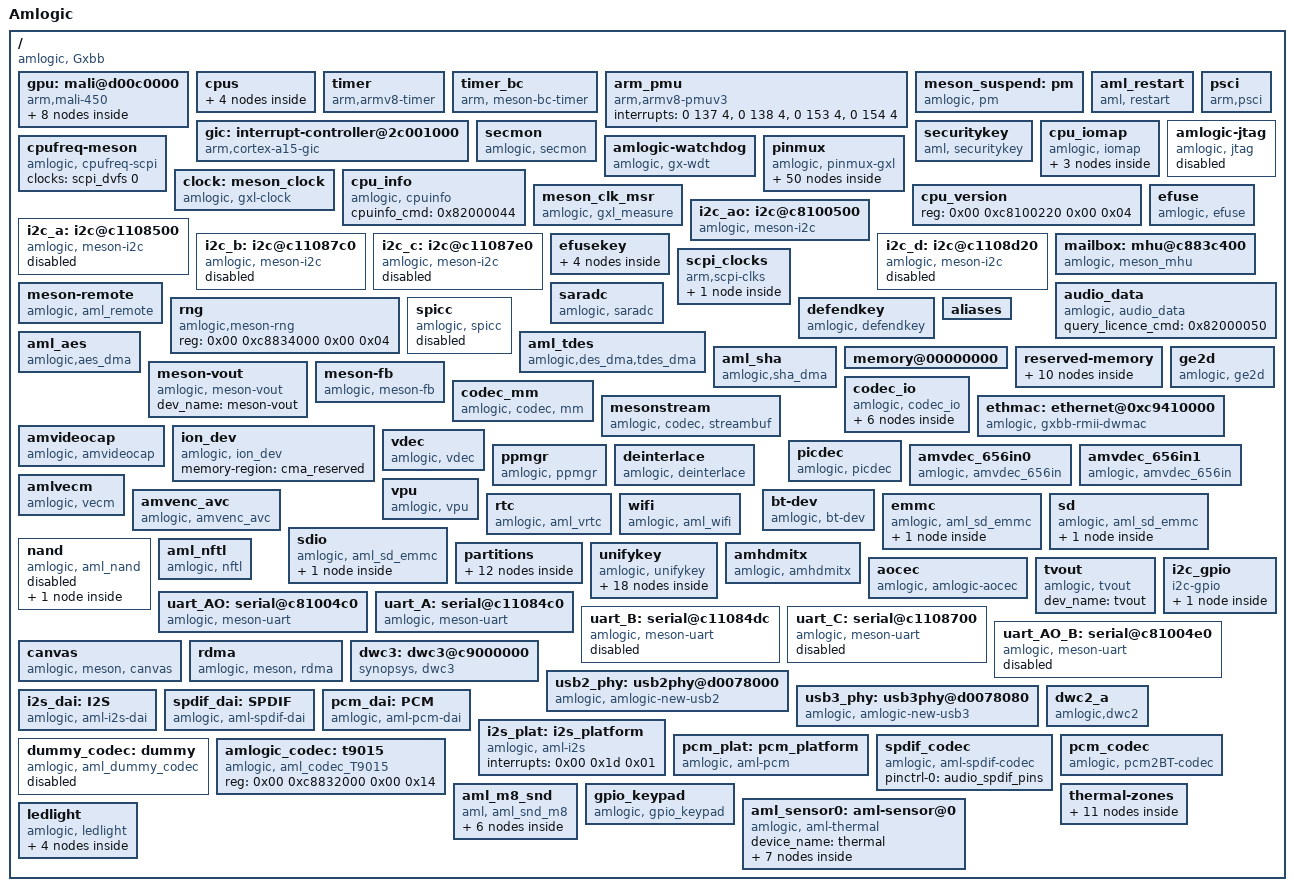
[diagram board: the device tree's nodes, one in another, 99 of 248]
/dts-v1/;

/ {
	le-dt-id = "gxl_p212_1g";
	model = "Amlogic";
	compatible = "amlogic, Gxbb";
	amlogic-dt-id = "gxl_p212_1g";
	interrupt-parent = < 0x01 >;
	#address-cells = < 0x02 >;
	#size-cells = < 0x02 >;

	gpu: mali@d00c0000 {
		#cooling-cells = < 0x02 >;	/* min followed by max */
		compatible = "arm,mali-450";
		interrupt-parent = < &gic >;
		reg = < 0 0xd00c0000 0 0x40000 >, /*mali APB bus base address*/
			 < 0 0xc1104440 0 0x01000 >, /*reset register*/
			 < 0 0xc8100000 0 0x01000 >, /*aobus base address for gpu pmu domain*/
			 < 0 0xc883c000 0 0x01000 >, /*hiubus base address for gpu clk cntl*/
			 < 0 0xc1104440 0 0x01000 >;
		interrupts = < 0 160 4 >, < 0 161 4 >, < 0 162 4 >, < 0 163 4 >,
				< 0 164 4 >, < 0 165 4 >, < 0 166 4 >, < 0 167 4 >,
				< 0 168 4 >, < 0 169 4 >;
		interrupt-names = "IRQGP", "IRQGPMMU", "IRQPP", "IRQPMU",
			"IRQPP0", "IRQPPMMU0", "IRQPP1", "IRQPPMMU1",
			"IRQPP2", "IRQPPMMU2";
		pmu_domain_config = < 0x01 0x02 0x04 0x04 0x00 0x00 0x00 0x00 0x00 0x01 0x02 0x00 >;
		pmu_switch_delay = < 0xffff >;
		num_of_pp = < 0x03 >;
		def_clock = < 0x03 >;
		sc_mpp = < 0x03 >;	/* number of pp used most of time.*/
		tbl = < &clk125_cfg &clk285_cfg &clk400_cfg &clk500_cfg &clk666_cfg &clk750_cfg >;

		clocks = < &clock CLK_FPLL_DIV3 >,
			< &clock CLK_FPLL_DIV4 >,
			< &clock CLK_FPLL_DIV5 >,
			< &clock CLK_FPLL_DIV7 >,
			< &clock GP0_PLL >,
			< &clock CLK_MALI >,
			< &clock CLK_MALI_0 >,
			< &clock CLK_MALI_1 >;
		clock-names = "fclk_div3", "fclk_div4", "fclk_div5", "fclk_div7", "gp0_pll", "clk_mali", "clk_mali_0", "clk_mali_1";

		/*control_interval x keep_count =  = 900 - 1000ms */
		control_interval = < 0xc8 >; //200

		 clk125_cfg: clk125_cfg {
			clk_freq = < 0x7735940 >; //125000000
			clk_parent = "fclk_div4";
			clkp_freq = < 0x1dcd6500 >; //500000000
			voltage = < 0x47e >; //1150
			keep_count = < 0x05 >;
			threshold = < 0x1e 0xfa >; //30 250
		};

		 clk250_cfg: clk250_cfg {
			clk_freq = < 0xee6b280 >; //250000000
			clk_parent = "fclk_div4";
			clkp_freq = < 0x1dcd6500 >; //500000000
			voltage = < 0x47e >; //1150
			keep_count = < 0x05 >;
			threshold = < 0x73 0xfa >; //115 250
			/*125 = 250*(125/250), 50 = 60-10*/
		};

		 clk285_cfg: clk285_cfg {
			clk_freq = < 0x10fcc140 >; //285000000
			clk_parent = "fclk_div7";
			clkp_freq = < 0x10fcc140 >; //285000000
			voltage = < 0x47e >; //1150
			keep_count = < 0x05 >;
			threshold = < 0x64 0xfa >; //100 250
			/*109 = 250*(125/285)*/
		};

		 clk400_cfg: clk400_cfg {
			clk_freq = < 0x17d78400 >; //400000000
			clk_parent = "fclk_div5";
			clkp_freq = < 0x17d78400 >; //400000000
			voltage = < 0x47e >; //1150
			keep_count = < 0x03 >;
			threshold = < 0xa8 0xfa >; //168 250
			/*178 = 250*(285/400)*/
		};

		 clk500_cfg: clk500_cfg {
			clk_freq = < 0x1dcd6500 >; //500000000
			clk_parent = "fclk_div4";
			clkp_freq = < 0x1dcd6500 >; //500000000
			voltage = < 0x47e >; //1150
			keep_count = < 0x02 >;
			threshold = < 0xbe 0xfa >; //190 250
			/*200 = 250*(400/500)*/
		};

		 clk666_cfg: clk666_cfg {
			clk_freq = < 0x27b25a80 >; //666000000
			clk_parent = "fclk_div3";
			clkp_freq = < 0x27b25a80 >; //666000000
			voltage = < 0x47e >; //1150
			keep_count = < 0x01 >;
			threshold = < 0xb1 0xfa >; //177 250
			/*187.5 = 250*(500/666.6)*/
		};

		 clk750_cfg: clk750_cfg {
			clk_freq = < 0x2c588a00 >; //744000000
			clk_parent = "gp0_pll";
			clkp_freq = < 0x2c588a00 >; //744000000
			voltage = < 0x47e >; //1150
			keep_count = < 0x01 >;
			threshold = < 0xd5 0xff >; //213 255
			/*223 = 250*(666.0/744.0), 223+7 = 230*/
		};

		 clk800_cfg: clk800_cfg {
			clk_freq = < 0x2f34f600 >; //792000000
			clk_parent = "gp0_pll";
			clkp_freq = < 0x2f34f600 >; //792000000
			voltage = < 0x47e >; //1150
			keep_count = < 0x01 >;
			threshold = < 0xe6 0xff >; //230 255
		};
	};

	cpus: cpus {
		#address-cells = < 0x02 >;
		#size-cells = < 0x00 >;
		#cooling-cells = < 2 >;	/* min followed by max */

		cpu0: cpu@0 {
			device_type = "cpu";
			compatible = "arm,cortex-a53", "arm,armv8";
			reg = < 0x00 0x00 >;
			enable-method = "psci";
		};

		cpu1: cpu@1 {
			device_type = "cpu";
			compatible = "arm,cortex-a53", "arm,armv8";
			reg = < 0x00 0x01 >;
			enable-method = "psci";
		};

		cpu2: cpu@2 {
			device_type = "cpu";
			compatible = "arm,cortex-a53", "arm,armv8";
			reg = < 0x00 0x02 >;
			enable-method = "psci";
		};

		cpu3: cpu@3 {
			device_type = "cpu";
			compatible = "arm,cortex-a53", "arm,armv8";
			reg = < 0x00 0x03 >;
			enable-method = "psci";
		};
	};

	timer {
		compatible = "arm,armv8-timer";
		interrupts = < GIC_PPI 13 0xff01 >, 
				 < GIC_PPI 14 0xff01 >,
				 < GIC_PPI 11 0xff01 >,
				 < GIC_PPI 10 0xff01 >;
	};	/* GIC_PPI: 1*/

	timer_bc {
		compatible = "arm, meson-bc-timer";
		reg = < 0x00 0xc1109990 0x00 0x04
			0x00 0xc1109994 0x00 0x04 >;
		timer_name = "Meson TimerF";
		clockevent-rating = < 0x12c >;
		clockevent-shift = < 0x14 >;
		clockevent-features = < 0x23 >;
		interrupts = < 0x00 0x3c 0x01 >;
		bit_enable = < 0x10 >;
		bit_mode = < 0x0c >;
		bit_resolution = < 0x00 >;
	};

	arm_pmu {
		compatible = "arm,armv8-pmuv3";
		interrupts = < 0 137 4 >,
				 < 0 138 4 >,
				 < 0 153 4 >,
				 < 0 154 4 >;
	};

	meson_suspend: pm {
		compatible = "amlogic, pm";
		device_name = "aml_pm";
		gxbaby-suspend;
		reg = < 0x00 0xc81000a8 0x00 0x04
			0x00 0xc810023c 0x00 0x04 >;
	};

	gic: interrupt-controller@2c001000 {
		compatible = "arm,cortex-a15-gic", "arm,cortex-a9-gic";
		#interrupt-cells = < 0x03 >;
		#address-cells = < 0x00 >;
		interrupt-controller;
		reg = < 0x00 0xc4301000 0x00 0x1000
			0x00 0xc4302000 0x00 0x100 >;
		interrupts = < GIC_PPI 0x09 0xf04 >;	/* GIC_PPI: 1*/
	};

	aml_restart {
		compatible = "aml, restart";
		sys_reset = < 0x84000009 >;
		sys_poweroff = < 0x84000008 >;
	};

	psci {
		compatible = "arm,psci";
		method = "smc";
		cpu_suspend = < 0xc4000001 >;
		cpu_off = < 0x84000002 >;
		cpu_on = < 0xc4000003 >;
		migrate = < 0xc4000005 >;
	};

	secmon {
		compatible = "amlogic, secmon";
		memory-region = < &secmon_reserved >;
		in_base_func = < 0x82000020 >;
		out_base_func = < 0x82000021 >;
	};

	securitykey {
		compatible = "aml, securitykey";
		storage_query = < 0x82000060 >;
		storage_read = < 0x82000061 >;
		storage_write = < 0x82000062 >;
		storage_tell = < 0x82000063 >;
		storage_verify = < 0x82000064 >;
		storage_status = < 0x82000065 >;
		storage_list = < 0x82000067 >;
		storage_remove = < 0x82000068 >;
		storage_in_func = < 0x82000023 >;
		storage_out_func = < 0x82000024 >;
		storage_block_func = < 0x82000025 >;
		storage_size_func = < 0x82000027 >;
	};

	cpu_iomap {
		compatible = "amlogic, iomap";
		#address-cells = < 0x02 >;
		#size-cells = < 0x02 >;
		ranges;

		io_cbus_base {
			reg = < 0x00 0xc1100000 0x00 0x100000 >;
		};

		io_apb_base {
			reg = < 0x00 0xd0000000 0x00 0x200000 >;
		};

		io_aobus_base {
			reg = < 0x00 0xc8100000 0x00 0x100000 >;
		};
	};

	cpufreq-meson {
		compatible = "amlogic, cpufreq-scpi";
		status = "okay";
		clocks = < &scpi_dvfs 0 >;
		clock-names = "cpu_clk";
	};

	amlogic-watchdog {
		compatible = "amlogic, gx-wdt";
		status = "okay";
		default_timeout = < 0x0a >;
		reset_watchdog_method = < 1 >; //0: sysfs,1: kernel
		reset_watchdog_time = < 0x02 >;
		shutdown_timeout = < 0x0a >;
		firmware_timeout = < 0x06 >;
		suspend_timeout = < 0x06 >;
		reg = < 0x00 0xc11098d0 0x00 0x10 >;
		clocks = < &clock CLK_XTAL >;
	};

	amlogic-jtag {
		compatible = "amlogic, jtag";
		status = "disabled";
		pinctrl-names = "jtag_apao_pins", "jtag_apee_pins";
		pinctrl-0 = < &jtag_apao_pins >;
		pinctrl-1 = < &jtag_apee_pins >;
	};

	clock: meson_clock {
		compatible = "amlogic, gxl-clock";
		reg = < 0x0 0xc883c000 0x0 0x1000 >,	/* HIU BUS */
			 < 0x0 0xc8100000 0x0 0x1000 >;	/* AOBUS */
		#clock-cells = < 0x01 >;
		#reset-cells = < 0x01 >;
		sys_max = < 0x5b8d8000 >;
	};

	cpu_info {
		compatible = "amlogic, cpuinfo";
		cpuinfo_cmd = < 0x82000044 >;
	};

	pinmux: pinmux {
		compatible = "amlogic, pinmux-gxl";
		dev_name = "pinmux";
		#pinmux-cells = < 0x02 >;
		#address-cells = < 0x02 >;
		#size-cells = < 0x02 >;
		reg = < 0x00 0xc1109880 0x00 0x10 >;
		ranges;

		gpio: banks@c11080b0 {
			reg = < 0x0 0xc88344b0 0x0 0x28 >,
				 < 0x0 0xc88344e8 0x0 0x14 >,
				 < 0x0 0xc8834520 0x0 0x14 >,
				 < 0x0 0xc8834430 0x0 0x40 >;
			reg-names = "mux", "pull", "pull-enable", "gpio";
			gpio-controller;
			#gpio-cells = < 0x02 >;
		};

		gpio_ao: ao-bank@c1108030 {
			reg = < 0x0 0xc8100014 0x0 0x8 >,
				 < 0x0 0xc810002c 0x0 0x4 >,
				 < 0x0 0xc8100024 0x0 0x8 >;
			reg-names = "mux", "pull", "gpio";
			gpio-controller;
			#gpio-cells = < 0x02 >;
		};

		external_eth_pins {
			amlogic,setmask = < 0x04 0xfffc00 >;
			amlogic,clrmask = < 0x04 0x3fc 0x03 0xffcff800 >;
			amlogic,pins = "GPIOZ_0", "GPIOZ_1", "GPIOZ_2", "GPIOZ_3", "GPIOZ_4", "GPIOZ_5", "GPIOZ_6",
			"GPIOZ_7", "GPIOZ_8", "GPIOZ_9", "GPIOZ_10", "GPIOZ_11", "GPIOZ_12", "GPIOZ_13";
		};

		internal_eth_pins: internal_eth_pins {
			amlogic,setmask = < 0x04 0x3000000 >;
			amlogic,clrmask = < 0x03 0x300000 >;
			amlogic,pins = "GPIOZ_14", "GPIOZ_15";
		};

		jtag_apao_pins: jtag_apao_pin {
			amlogic,clrmask = < 0x06 0x7fe0000 >;
			amlogic,pins = "GPIOH_6", "GPIOH_7", "GPIOH_8", "GPIOH_9";
		};

		jtag_apee_pins: jtag_apee_pin{
			amlogic,clrmask = < 0x06 0x3c >;
			amlogic,pins = "CARD_0", "CARD_1", "CARD_2", "CARD_3";
		};

		remote_pin {
			amlogic,setmask = < 0x10 0x01 >;
			amlogic,pins = "GPIOAO_7";
		};

		ao_uart {
			amlogic,setmask = < 0x10 0x1800 >;
			amlogic,pins = "GPIOAO_0", "GPIOAO_1";
		};

		ao_b_uart_pins: ao_b_uart {
			amlogic,setmask = < 0x10 0x1800000 >;
			amlogic,pins = "GPIOAO_4", "GPIOAO_5";
		};

		uart_a_pins: a_uart {
			amlogic,setmask = < 0x05 0xf0000 >;
			amlogic,clrmask = < 0x05 0x3c0 >;
			amlogic,pins = "GPIOX_12", "GPIOX_13", "GPIOX_14", "GPIOX_15";
		};

		b_uart_pins: b_uart {
			amlogic,setmask = < 0x02 0x18000 >;
			amlogic,pins = "GPIODV_24", "GPIODV_25";
		};

		c_uart_pins: c_uart {
			amlogic,setmask = < 0x05 0x3000 >;
			amlogic,pins = "GPIOX_8", "GPIOX_9";
		};

		wifi_32k_pins: wifi_32k_pins {
			amlogic,setmask = < 0x05 0x8000 >;
			amlogic,pins = "GPIOX_16";
		};

		sd_clk_cmd_pins: sd_clk_cmd_pins{
			amlogic,setmask = < 0x06 0x0c 0x10 0x1800 >;
			amlogic,pins = "CARD_2", "CARD_3";	/* CARD_2: CLK, CARD_3: CMD */
			amlogic,enable-output = < 0x01 >;	/* 0: output, 1: input */
			amlogic,pullup = < 0x01 >;
			amlogic,pullupen = < 0x01 >;
		};

		sd_all_pins: sd_all_pins{
			amlogic,setmask = < 0x06 0x3f 0x10 0x1800 >;
			amlogic,clrmask = < 0x06 0xfc0 >;
			amlogic,pins = "CARD_0", "CARD_1", "CARD_2", "CARD_3", "CARD_4", "CARD_5";
			amlogic,enable-output = < 0x01 >;	/* 0: output, 1: input */
			amlogic,pullup = < 0x01 >;
			amlogic,pullupen = < 0x01 >;
		};

		sd_1bit_pins: sd_1bit_pins{
			amlogic,setmask = < 0x06 0x1c 0x10 0x1800 >;
			amlogic,clrmask = < 0x06 0xcc3 >;
			amlogic,pins = "CARD_1", "CARD_2", "CARD_3";
			amlogic,enable-output = < 0x01 >;	/* 0: output, 1: input */
			amlogic,pullup = < 0x01 >;
			amlogic,pullupen = < 0x01 >;
		};

		sd_clk_cmd_uart_pins: sd_clk_cmd_uart_pins{
			amlogic,setmask = < 0x06 0x30c >;
			amlogic,clrmask = < 0x06 0xcc3 0x10 0x1800 >;
			amlogic,pins = "CARD_2", "CARD_3";	/* CARD_2: CLK, CARD_3: CMD */
			amlogic,enable-output = < 0x01 >;	/* 0: output, 1: input */
			amlogic,pullup = < 0x01 >;
			amlogic,pullupen = < 0x01 >;
		};

		sd_1bit_uart_pins: sd_1bit_uart_pins{
			amlogic,setmask = < 0x06 0x31c >;
			amlogic,clrmask = < 0x06 0xcc3 0x10 0x1800 >;
			amlogic,pins = "CARD_1", "CARD_2", "CARD_3";
			amlogic,enable-output = < 0x01 >;	/* 0: output, 1: input */
			amlogic,pullup = < 0x01 >;
			amlogic,pullupen = < 0x01 >;
		};

		sd_to_ao_uart_pins: sd_to_ao_uart_pins {
			amlogic,setmask = < 0x10 0x1800 >;
			amlogic,clrmask = < 0x06 0x300 >;
			amlogic,pins = "GPIOAO_0", "GPIOAO_1";
			amlogic,enable-output = < 0x01 >;
			amlogic,pullup = < 0x01 >;
			amlogic,pullupen = < 0x01 >;
		};

		ao_to_sd_uart_pins: ao_to_sd_uart_pins {
			amlogic,setmask = < 0x06 0x300 >;
			amlogic,clrmask = < 0x10 0x1800 0x06 0xcc3 >;
			amlogic,pins = "CARD_4", "CARD_5";
			amlogic,enable-output = < 0x01 >;	/* 0: output, 1: input */
			amlogic,pullup = < 0x01 >;
			amlogic,pullupen = < 0x01 >;
		};
		/* switch jtag pins to card from apao */
		ao_to_sd_jtag_pins: ao_to_sd_jtag_pins{
			amlogic,setmask = < 0x06 0x300 >;	/*set for uart-ee, fixme? */
			amlogic,clrmask = < 0x06 0xcff 0x10 0x1800 >;	/* clear for jtag */ /* clear for uart-ee, fixme? */
			amlogic,pins = "CARD_4", "CARD_5";	/* should be CARD_0/1/2/3 */
			amlogic,enable-output = < 0x01 >;	/* 0: output, 1: input */
			amlogic,pullup = < 0x01 >;
			amlogic,pullupen = < 0x01 >;
		};

		sd_to_ao_jtag_pins: sd_to_ao_jtag_pins {
			amlogic,setmask = < 0x10 0x1800 >;
			amlogic,clrmask = < 0x06 0xfc0 >;
			amlogic,pins = "GPIOAO_0", "GPIOAO_1";
			amlogic,enable-output = < 0x01 >;
			amlogic,pullup = < 0x01 >;
			amlogic,pullupen = < 0x01 >;
		};

		emmc_clk_cmd_pins: emmc_clk_cmd_pins{
			amlogic,setmask = < 0x07 0x60000000 >;
			amlogic,clrmask = < 0x07 0xe0 >;
			amlogic,pins = "BOOT_8", "BOOT_10";	/** BOOT_10: CMD, BOOT_8: CLK */
			amlogic,enable-output = < 0x01 >;	/** 0: output, 1: input */
			amlogic,pullup = < 0x01 >;
			amlogic,pullupen = < 0x01 >;
		};

		emmc_conf_pull_up: emmc_conf_pull_up{
			amlogic,pins = "BOOT_0", "BOOT_1", "BOOT_2", "BOOT_3", "BOOT_4",
					"BOOT_5", "BOOT_6", "BOOT_7", "BOOT_8", "BOOT_10";
			amlogic,pullup = < 0x01 >;
			amlogic,pullupen = < 0x01 >;
		};

		emmc_conf_pull_done: emmc_conf_pull_done{
			amlogic,pins = "BOOT_15";
			amlogic,pullup = < 0x00 >;
			amlogic,pullupen = < 0x01 >;
		};

		emmc_all_pins: emmc_all_pins {
			amlogic,setmask = < 0x07 0xf0000000 >;
			amlogic,clrmask = < 0x07 0xe0 >;
			amlogic,pins = "BOOT_0", "BOOT_1", "BOOT_2", "BOOT_3", "BOOT_4", "BOOT_5", "BOOT_6", "BOOT_7", "BOOT_8", "BOOT_10", "BOOT_15";
			amlogic,enable-output = < 0x01 >;
		};

		sdio_clk_cmd_pins: sdio_clk_cmd_pins {
			amlogic,setmask = < 0x05 0xc000000 >;
			amlogic,pins = "GPIOX_4", "GPIOX_5";
			amlogic,enable-output = < 0x01 >;
			amlogic,pullup = < 0x01 >;
			amlogic,pullupen = < 0x01 >;
		};

		sdio_all_pins: sdio_all_pins {
			amlogic,setmask = < 0x05 0xfc000000 >;
			amlogic,pins = "GPIOX_0", "GPIOX_1", "GPIOX_2", "GPIOX_3", "GPIOX_4", "GPIOX_5";
			amlogic,enable-output = < 0x01 >;
			amlogic,pullup = < 0x01 >;
			amlogic,pullupen = < 0x01 >;
		};

		conf_nand_pulldown: conf_nand_pulldown {
			amlogic,pins = "BOOT_0", "BOOT_1", "BOOT_2", "BOOT_3", "BOOT_4", "BOOT_5", "BOOT_6", "BOOT_7", "BOOT_15";
			amlogic,pullup = < 0x00 >;
			amlogic,pullupen = < 0x01 >;
		};

		conf_nand_pullup: conf_nand_pullup {
			amlogic,pins = "BOOT_8", "BOOT_10";
			amlogic,pullup = < 0x01 >;
			amlogic,pullupen = < 0x01 >;
		};

		all_nand_pins: all_nand_pins {
			amlogic,setmask = < 0x07 0x800000ff >;
			amlogic,clrmask = < 0x07 0x70ffbc00 >;
			amlogic,pins = "BOOT_0", "BOOT_1", "BOOT_2", "BOOT_3", "BOOT_4", "BOOT_5", "BOOT_6", "BOOT_7", "BOOT_8", "BOOT_9", "BOOT_10", "BOOT_11", "BOOT_12", "BOOT_13", "BOOT_14", "BOOT_15";
			amlogic,enable-output = < 0x01 >;
		};

		nand_cs: nand_cs {
			amlogic,setmask = < 0x07 0xc0 >;
			amlogic,clrmask = < 0x07 0x40040000 >;
			amlogic,pins = "BOOT_8", "BOOT_9";
		};

		hdmitx_hpd: hdmitx_hpd {
			amlogic,setmask = < 0x06 0x80000000 >;
			amlogic,pins = "GPIOH_0";
		};

		hdmitx_ddc: hdmitx_ddc {
			amlogic,setmask = < 0x06 0x30000000 >;
			amlogic,pins = "GPIOH_1", "GPIOH_2";
		};

		hdmitx_aocec: hdmitx_aocec {
			amlogic,setmask = < 0x10 0x8000 >;
			amlogic,clrmask = < 0x10 0x24000 0x11 0x01 >;
			amlogic,pins = "GPIOAO_8";
		};

		hdmitx_eecec: hdmitx_eecec {
			amlogic,setmask = < 0x10 0x4000 >;
			amlogic,clrmask = < 0x10 0x28000 0x11 0x01 >;
			amlogic,pins = "GPIOAO_8";
		};

		ao_i2c_master: ao_i2c{
			amlogic,setmask = < AO 0x60 >;	/* AO: 0x10 */
			amlogic,clrmask = < AO 0x1800006 >;
			amlogic,pins = "GPIOAO_4", "GPIOAO_5";
		};

		i2c_a_master: i2c_a{
			amlogic,setmask = < 0x01 0xc000 >;
			amlogic,clrmask = < 0x03 0x18 0x02 0x18000 0x02 0xc0 0x01 0x600000 >;
			amlogic,pins = "GPIODV_24", "GPIODV_25";
		};

		i2c_b_master: i2c_b{
			amlogic,setmask = < 0x01 0x3000 >;
			amlogic,clrmask = < 0x02 0x6000 0x01 0x1c0000 >;
			amlogic,pins = "GPIODV_26", "GPIODV_27";
		};

		i2c_c_master: i2c_c{
			amlogic,setmask = < 0x01 0xc00 >;
			amlogic,clrmask = < 0x02 0x1800 0x01 0x200 0x02 0x20 >;
			amlogic,pins = "GPIODV_28", "GPIODV_29";
		};

		i2c_d_master: i2c_d{
			amlogic,setmask = < 0x05 0x30 >;
			amlogic,clrmask = < 0x05 0x300c03 >;
			amlogic,pins = "GPIOX_10", "GPIOX_11";
		};

		spicc_pins_z11z12z13 {
			amlogic,setmask = < 0x04 0x1c >;
			amlogic,clrmask = < 0x03 0x800 0x04 0x1c00 >;
			amlogic,pins = "GPIOZ_11", "GPIOZ_12", "GPIOZ_13";
		};

		spicc_pulldown_z11z12z13 {
			amlogic,pins = "GPIOZ_11", "GPIOZ_12", "GPIOZ_13";
			amlogic,pullup = < 0x00 >;
			amlogic,pullupen = < 0x01 >;
		};

		spicc_pullup_z11z12z13 {
			amlogic,pins = "GPIOZ_11", "GPIOZ_12", "GPIOZ_13";
			amlogic,pullup = < 0x01 >;
			amlogic,pullupen = < 0x01 >;
		};

		spicc_pins_x8x9x11 {
			amlogic,setmask = < 0x05 0x0d >;
			amlogic,clrmask = < 0x05 0xd03430 0x06 0x0d >;
			amlogic,pins = "GPIOX_8", "GPIOX_9", "GPIOX_11";
		};

		spicc_pulldown_x8x9x11 {
			amlogic,pins = "GPIOX_8", "GPIOX_9", "GPIOX_11";
			amlogic,pullup = < 0x00 >;
			amlogic,pullupen = < 0x01 >;
		};

		spicc_pullup_x8x9x11 {
			amlogic,pins = "GPIOX_8", "GPIOX_9", "GPIOX_11";
			amlogic,pullup = < 0x01 >;
			amlogic,pullupen = < 0x01 >;
		};

		audio_pins: audio_pin {
			amlogic,setmask = < 0x06 0x7800000 >;
			amlogic,clrmask = < 0x06 0x7e0000 >;
			amlogic,pins = "GPIOH_6", "GPIOH_7", "GPIOH_8", "GPIOH_9";
		};

		audio_spdif_pins: audio_pin1 {
			amlogic,setmask = < 0x06 0x10000000 >;	/*spdif_out*/
			amlogic,clrmask = < 0x06 0x8000000 >;
			amlogic,pins = "GPIOH_4";
		};

		audio_btpcm_pins: audio_btpcm_pins {
			amlogic,setmask = < 0x05 0xf00000 >;
			amlogic,clrmask = < 0x05 0x3c33 >;
			amlogic,pins = "GPIOX_8", "GPIOX_9", "GPIOX_10", "GPIOX_11";
		};
	};	/* end of pinmux */

	cpu_version {
		reg = < 0x00 0xc8100220 0x00 0x04 >;
	};

	meson_clk_msr {
		compatible = "amlogic, gxl_measure";
		reg = < 0x00 0xc110875c 0x00 0x04
			0x00 0xc1108764 0x00 0x04 >;
	};

	i2c_ao: i2c@c8100500{ /*I2C-AO*/
		compatible = "amlogic, meson-i2c";
		dev_name = "i2c-AO";
		status = "okay";
		reg = < 0x00 0xc8100500 0x00 0x1d >;
		device_id = < 0x00 >;
		pinctrl-names = "default";
		pinctrl-0 = < &ao_i2c_master >;
		#address-cells = < 0x01 >;
		#size-cells = < 0x00 >;
		use_pio = < 0x00 >;
		master_i2c_speed = < 0x493e0 >;
		clocks = < &clock CLK_81 >;
		clock-names = "clk_i2c";
		resets = < &clock GCLK_IDX_I2C >;	/* GCLK_IDX_I2C: 0x09 */
	};

	i2c_a: i2c@c1108500 { /*I2C-A*/
		compatible = "amlogic, meson-i2c";
		dev_name = "i2c-A";
		status = "disabled";
		reg = < 0x00 0xc1108500 0x00 0x20 >;
		device_id = < 0x01 >;
		pinctrl-names = "default";
		pinctrl-0 = < &i2c_a_master >;	/*p200 i2c-A multiplex with usb PWR*/
		#address-cells = < 0x01 >;
		#size-cells = < 0x00 >;
		use_pio = < 0x00 >;
		master_i2c_speed = < 0x493e0 >;
		clocks = < &clock CLK_81 >;
		clock-names = "clk_i2c";
		resets = < &clock GCLK_IDX_I2C >;	/* GCLK_IDX_I2C: 0x09 */
	};

	i2c_b: i2c@c11087c0 { /*I2C-B*/
		compatible = "amlogic, meson-i2c";
		dev_name = "i2c-B";
		status = "disabled";
		reg = < 0x00 0xc11087c0 0x00 0x20 >;
		device_id = < 0x02 >;
		pinctrl-names = "default";
		pinctrl-0 = < &i2c_b_master >;
		#address-cells = < 0x01 >;
		#size-cells = < 0x00 >;
		use_pio = < 0x00 >;
		master_i2c_speed = < 0x493e0 >;
		clocks = < &clock CLK_81 >;
		clock-names = "clk_i2c";
		resets = < &clock GCLK_IDX_I2C >;	/* GCLK_IDX_I2C: 0x09 */
	};

	i2c_c: i2c@c11087e0 { /*I2C-C*/
		compatible = "amlogic, meson-i2c";
		dev_name = "i2c-C";
		status = "disabled";
		reg = < 0x00 0xc11087e0 0x00 0x20 >;
		device_id = < 0x03 >;
		pinctrl-names = "default";
		pinctrl-0 = < &i2c_c_master >;
		#address-cells = < 0x01 >;
		#size-cells = < 0x00 >;
		use_pio = < 0x00 >;
		master_i2c_speed = < 0x493e0 >;
		clocks = < &clock CLK_81 >;
		clock-names = "clk_i2c";
		resets = < &clock GCLK_IDX_I2C >;	/* GCLK_IDX_I2C: 0x09 */
	};

	i2c_d: i2c@c1108d20 { /*I2C-D*/
		compatible = "amlogic, meson-i2c";
		dev_name = "i2c-D";
		status = "disabled";
		reg = < 0x00 0xc1108d20 0x00 0x20 >;
		device_id = < 0x04 >;
		pinctrl-names = "default";
		pinctrl-0 = < &i2c_d_master >;
		#address-cells = < 0x01 >;
		#size-cells = < 0x00 >;
		use_pio = < 0x00 >;
		master_i2c_speed = < 0x493e0 >;
		clocks = < &clock CLK_81 >;
		clock-names = "clk_i2c";
		resets = < &clock GCLK_IDX_I2C >;	/* GCLK_IDX_I2C: 0x09 */
	};

	efuse {
		compatible = "amlogic, efuse";
		read_cmd = < 0x82000030 >;
		write_cmd = < 0x82000031 >;
		get_max_cmd = < 0x82000033 >;
		key = < &efusekey >;
		resets = < &clock GCLK_IDX_EFUSE >;	/* GCLK_IDX_EFUSE: 0x3e */
		reset-names = "efuse_clk";
		status = "okay";
	};

	efusekey: efusekey {
		keynum = < 0x04 >;
		key0 = < &key_0 >;
		key1 = < &key_1 >;
		key2 = < &key_2 >;
		key3 = < &key_3 >;

		key_0: key_0{
			keyname = "mac";
			offset = < 0x00 >;
			size = < 0x06 >;
		};

		key_1: key_1{
			keyname = "mac_bt";
			offset = < 0x06 >;
			size = < 0x06 >;
		};

		key_2: key_2{
			keyname = "mac_wifi";
			offset = < 0x0c >;
			size = < 0x06 >;
		};

		key_3: key_3{
			keyname = "usid";
			offset = < 0x12 >;
			size = < 0x10 >;
		};
	};

	mailbox: mhu@c883c400 {
		compatible = "amlogic, meson_mhu";
		reg = < 0x0 0xc883c400 0x0 0x4c >,	/* MHU registers */
			 < 0x0 0xc8013000 0x0 0x800 >;	/* Payload area */
		interrupts = < 0 209 IRQ_TYPE_EDGE_RISING >,	/* low priority interrupt */
				 < 0 210 IRQ_TYPE_EDGE_RISING >;	/* high priority interrupt */
		#mbox-cells = < 0x01 >;
		mbox-names = "cpu_to_scp_low", "cpu_to_scp_high";
		mboxes = < &mailbox 0 &mailbox 1 >;
	};

	scpi_clocks {
		compatible = "arm,scpi-clks";

		scpi_dvfs: scpi_clocks@0 {
			compatible = "arm,scpi-clk-indexed";
			#clock-cells = < 0x01 >;
			clock-indices = < 0x00 >;
			clock-output-names = "vcpu";
		};
	};

	meson-remote {
		compatible = "amlogic, aml_remote";
		dev_name = "meson-remote";
		status = "okay";
		remote_ao_offset = < 0x580 >;
		interrupts = < 0x00 0xc4 0x01 >;
		pinctrl-names = "default";
		pinctrl-0 = < 0x18 >;
	};

	rng {
		compatible = "amlogic,meson-rng";
		reg = < 0x00 0xc8834000 0x00 0x04 >;
	};

	audio_data: audio_data {
		compatible = "amlogic, audio_data";
		query_licence_cmd = < 0x82000050 >;
		status = "okay";
	};

	saradc: saradc {
		compatible = "amlogic, saradc";
		status = "okay";
		interrupts = < 0x00 0x09 0x01 >;
		interrupt-names = "saradc_int";
		clocks = < &clock CLK_XTAL >;
		clock-names = "saradc_clk";
		resets = < &clock GCLK_IDX_SARADC >;	/* GCLK_IDX_SARADC: 0x56 */
		reg = < 0x00 0xc1108680 0x00 0x30
			0x00 0xc883c3d8 0x00 0x08 >;
	};

	defendkey: defendkey {
		compatible = "amlogic, defendkey";
		reg = < 0x00 0xc8834500 0x00 0x04 >;	/*RAND64_ADDR0*/
		mem_size = < 0x00 0x100000 >;
		status = "okay";
	};

	spicc: spicc {
		compatible = "amlogic, spicc";
		status = "disabled";
		reg = < 0x00 0xc1108d80 0x00 0x28 >;
		resets = < &clock GCLK_IDX_SPICC >;	/* GCLK_IDX_SPICC: 0x08 */
		// reset-names = "spicc_clk";
		clocks = < &clock CLK_81 >;
		clock-names = "spicc_clk";
		interrupts = < 0x00 0x51 0x01 >;
		device_id = < 0x00 >;
		//enhance = < 1 >;
	};

	aml_aes {
		compatible = "amlogic,aes_dma";
		dev_name = "aml_aes_dma";
		interrupts = < 0x00 0xbc 0x01
				0x00 0xbd 0x01 >;
		reg = < 0x00 0xc883e000 0x00 0x28 >;
	};

	aml_tdes {
		compatible = "amlogic,des_dma,tdes_dma";
		dev_name = "aml_tdes_dma";
		interrupts = < 0x00 0xbc 0x01 0x00 0xbd 0x01 >;
		reg = < 0x00 0xc883e000 0x00 0x28 >;
	};

	aml_sha {
		compatible = "amlogic,sha_dma";
		dev_name = "aml_sha_dma";
		interrupts = < 0x00 0xbc 0x01 0x00 0xbd 0x01 >;
		reg = < 0x00 0xc883e000 0x00 0x28 >;
	};

	aliases {
		serial0 = &uart_AO;
		serial1 = &uart_A;
		serial2 = &uart_B;
		serial3 = &uart_C;
		serial4 = &uart_AO_B;
	};

	memory@00000000 {
		device_type = "memory";
		linux,usable-memory = < 0x00 0x100000 0x00 0x3ff00000 >;
	};

	reserved-memory {
		#address-cells = < 0x02 >;
		#size-cells = < 0x02 >;
		ranges;
		/* global autoconfigured region for contiguous allocations */
		secmon_reserved: linux,secmon {
			compatible = "amlogic, aml_secmon_memory";
			reg = < 0x00 0x10000000 0x00 0x200000 >;
			no-map;
		};

		secos_reserved: linux,secos {
			status = "disable";
			compatible = "amlogic, aml_secos_memory";
			reg = < 0x00 0x5300000 0x00 0x2000000 >;
			no-map;
		};

		pstore: aml_pstore {
			compatible = "amlogic, pstore";
			reg = < 0x00 0x7300000 0x00 0x100000 >;
			no-map;
		};

		fb_reserved: linux,meson-fb {
			compatible = "amlogic, fb-memory";
			size = < 0x00 0x2000000 >;
			no-map;
		};

		di_reserved: linux,di {
			compatible = "amlogic, di-mem";
			/** 10x3133440 = 30M(0x1e) support 8bit **/
			size = < 0x00 0x1e00000 >;
		};

		carveout_reserved: linux,carveout-reserve {
			compatible = "amlogic, idev-mem";
			size = < 0x00 0x2000000 >;
		};
		/* POST PROCESS MANAGER */
		ppmgr_reserved: linux,ppmgr {
			compatible = "shared-dma-pool";
			size = < 0x00 0x00 >;
		};

		codec_mm_cma: linux,codec_mm_cma {
			compatible = "shared-dma-pool";
			reusable;
			size = < 0x00 0xc000000 >;
			alignment = < 0x00 0x400000 >;
			linux,contiguous-region;
		};
		picdec_cma_reserved: linux,picdec {
			compatible = "shared-dma-pool";
			reusable;
			size = < 0x00 0x00 >;
			alignment = < 0x00 0x00 >;
			linux,contiguous-region;
		};
		/* codec shared reserved */
		codec_mm_reserved: linux,codec_mm_reserved {
			compatible = "amlogic, codec-mm-reserved";
			size = < 0x00 0x4100000 >;
			alignment = < 0x00 0x100000 >;
 			//no-map;
		};
	};

	meson-vout {
		compatible = "amlogic, meson-vout";
		dev_name = "meson-vout";
		status = "okay";
	};

	meson-fb {
		compatible = "amlogic, meson-fb";
		memory-region = < &fb_reserved >;
		dev_name = "meson-fb";
		status = "okay";
		interrupts = < 0x00 0x03 0x01
				0x00 0x59 0x01 >;
		interrupt-names = "viu-vsync", "rdma";
		mem_size = < 0x1800000 0x100000 >;	/* fb0/fb1 memory size */
		display_mode_default = "1080p60hz";
		scale_mode = < 0x01 >;	/** 0: VPU free scale 1: OSD free scale 2: OSD super scale */
		display_size_default = < 0x780 0x438 0x780 0xca8 0x20 >; //1920*1080*4*3 = 0x17BB000
		//logo_addr = "0x3f851000";
	};

	ge2d {
		compatible = "amlogic, ge2d";
		dev_name = "ge2d";
		status = "okay";
		interrupts = < 0x00 0x96 0x01 >;
		interrupt-names = "ge2d";
		clocks = < &clock CLK_VAPB_0 >, < &clock CLK_GE2D >;
		clock-names = "clk_vapb_0", "clk_ge2d";
		resets = < &clock GCLK_IDX_GE2D >;	/* GCLK_IDX_GE2D: 0x34 */
		reset-names = "ge2d";
	};

	codec_io {
		compatible = "amlogic, codec_io";
		#address-cells = < 0x02 >;
		#size-cells = < 0x02 >;
		ranges;

		io_cbus_base {
			reg = < 0x00 0xc1100000 0x00 0x100000 >;
		};

		io_dos_base {
			reg = < 0x00 0xc8820000 0x00 0x10000 >;
		};

		io_hiubus_base {
			reg = < 0x00 0xc883c000 0x00 0x2000 >;
		};

		io_aobus_base {
			reg = < 0x00 0xc8100000 0x00 0x100000 >;
		};

		io_vcbus_base {
			reg = < 0x00 0xd0100000 0x00 0x40000 >;
		};

		io_dmc_base {
			reg = < 0x00 0xc8838000 0x00 0x400 >;
		};
	};

	codec_mm {
		compatible = "amlogic, codec, mm";
		memory-region = < &codec_mm_cma &codec_mm_reserved >;
		dev_name = "codec_mm";
		status = "okay";
	};

	ethmac: ethernet@0xc9410000 {
		compatible = "amlogic, gxbb-rmii-dwmac";
		reg = < 0x00 0xc9410000 0x00 0x10000
			0x00 0xc8834540 0x00 0x08
			0x00 0xc8834558 0x00 0x0c >;
		interrupts = < 0x00 0x08 0x01 >;
		phy-mode = "rmii";
		pinctrl-names = "internal_eth_pins";
		pinctrl-0 = < &internal_eth_pins >;
		mc_val = < 0x1800 >;
		resets = < &clock GCLK_IDX_ETHERNET >;	/* GCLK_IDX_ETHERNET: 0x23 */
		reset-names = "ethpower";
		interrupt-names = "macirq";
		clocks = < &clock CLK_81 >;
		clock-names = "ethclk81";
		internal_phy = < 0x01 >;
		wol = < 0 >;
	};

	mesonstream {
		compatible = "amlogic, codec, streambuf";
		dev_name = "mesonstream";
		status = "okay";
		resets = < &clock GCLK_IDX_HIU_PARSER_TOP
			&clock GCLK_IDX_VPU_INTR
			&clock GCLK_IDX_DEMUX
			&clock GCLK_IDX_DOS >;
		reset-names = "parser_top", "vpu_intr", "demux", "vdec";
	};

	amvideocap {
		compatible = "amlogic, amvideocap";
		dev_name = "amvideocap.0";
		status = "okay";
		max_size = < 0x08 >; //8M
	};

	ion_dev {
		compatible = "amlogic, ion_dev";
		memory-region = < &cma_reserved >;
	};

	vdec {
		compatible = "amlogic, vdec";
		dev_name = "vdec.0";
		status = "okay";
		interrupts = < 0x00 0x03 0x01
				0x00 0x17 0x01
				0x00 0x20 0x01
				0x00 0x2b 0x01
				0x00 0x2c 0x01
				0x00 0x2d 0x01 >;
		interrupt-names = "vsync", "demux", "parser", "mailbox_0", "mailbox_1", "mailbox_2";
	};

	picdec {
		compatible = "amlogic, picdec";
		memory-region = < &picdec_cma_reserved >;
		dev_name = "picdec";
		status = "okay";
	};

	ppmgr {
		compatible = "amlogic, ppmgr"; //to match of_device_id's compatible member
		memory-region = < &ppmgr_reserved >;
		dev_name = "ppmgr";
		status = "okay";
	};

	deinterlace {
		compatible = "amlogic, deinterlace";
		status = "okay";
		memory-region = < &di_reserved >;
		interrupts = < 0x00 0x2e 0x01
				0x00 0x06 0x01 >;
		interrupt-names = "de_irq", "timerc";
		/* nr_size(byte) = 1920*544*2(yuv422 8bit) | 1920*544*2*12/8(yuv422 10bit) | 1920*544*2*10/8(yuv422 10bit full pack mode) */
		/* mtn_size(byte) = 1920*544/2 */
		/* count_size(byte) = 1920*544/2 */
		buffer-size = < 0x2fd000 >;
		hw-version = < 0x02 >;
	};

	amvdec_656in0 {
		compatible = "amlogic, amvdec_656in";
		dev_name = "amvdec_656in0";
		status = "ok";
		reg = < 0x00 0xd0048000 0x00 0x7c >;
		clocks = < &clock CLK_FPLL_DIV2 >,
			< &clock CLK_BT656_CLK0 >;
		clock-names = "fclk_div2", "cts_bt656_clk0";
		bt656_id = < 0x00 >;
	};

	amvdec_656in1 {
		compatible = "amlogic, amvdec_656in";
		dev_name = "amvdec_656in1";
		status = "ok";
		reg = < 0x00 0xd0050000 0x00 0x7c >;
		clocks = < &clock CLK_FPLL_DIV2 >,
			< &clock CLK_BT656_CLK1 >;
		clock-names = "fclk_div2", "cts_bt656_clk1";
		bt656_id = < 0x01 >;
	};

	amlvecm {
		compatible = "amlogic, vecm";
		dev_name = "aml_vecm";
		status = "okay";
		gamma_en = < 0x00 >;	/*1: enabel ;0: disable*/
		wb_en = < 0x00 >;	/*1: enabel ;0: disable*/
		cm_en = < 0x00 >;	/*1: enabel ;0: disable*/
	};

	amvenc_avc {
		compatible = "amlogic, amvenc_avc";
		//memory-region = < &amvenc_avc_reserved >;
		//memory-region = < &avc_cma_reserved >;
		dev_name = "amvenc_avc";
		status = "okay";
		interrupts = < 0x00 0x2d 0x01 >;
		interrupt-names = "mailbox_2";
	};

	vpu {
		compatible = "amlogic, vpu";
		dev_name = "vpu";
		status = "ok";
		clk_level = < 0x07 >;
		/**	0: 100.0M	1: 166.7M	2: 200.0M
			3: 250.0M	4: 333.3M	5: 400.0M
			6: 500.0M	7: 666.7M */
	};
	//if use bt, open it
	bt-dev {
		compatible = "amlogic, bt-dev";
		dev_name = "bt-dev";
		status = "okay";
		gpio_reset = < &gpio		GPIOX_17		GPIO_ACTIVE_HIGH >; 
		/* GPIOX_17: 0x60, GPIO_ACTIVE_HIGH: 0 */
	};

	rtc {
		compatible = "amlogic, aml_vrtc";
		alarm_reg_addr = < 0xc81000a8 >;
		timer_e_addr = < 0xc1109988 >;
		init_date = "2021/01/01";
		status = "okay";
	};

	wifi {
		compatible = "amlogic, aml_wifi";
		dev_name = "aml_wifi";
		status = "okay";
		interrupt_pin = < &gpio		GPIOX_7		GPIO_ACTIVE_HIGH >;	/* GPIOX_7: 0x56 */
		interrupts = < 0x00 0x44 0x04 >;
		irq_trigger_type = "GPIO_IRQ_LOW";
		power_on_pin = < &gpio		GPIOX_6		GPIO_ACTIVE_HIGH >;	/* GPIOX_6: 0x55 */
		dhd_static_buf;	//if use bcm wifi, config dhd_static_buf and 32k as bellow
		pinctrl-names = "wifi_32k_pins";
		pinctrl-0 = < &wifi_32k_pins >;
	};

	emmc {
		compatible = "amlogic, aml_sd_emmc";
		dev_name = "aml_newsd.0";
		status = "okay";
		reg = < 0x00 0xd0074000 0x00 0x2000 >;
		interrupts = < 0x00 0xda 0x01 >;
		pinctrl-names = "emmc_clk_cmd_pins", "emmc_all_pins";
		pinctrl-0 = < &emmc_clk_cmd_pins >;
		pinctrl-1 = < &emmc_conf_pull_up &emmc_conf_pull_done &emmc_all_pins >;

		emmc {
			status = "disabled";
			pinname = "emmc";
			ocr_avail = < 0x200080 >;	/**VDD voltage 3.3 ~ 3.4 */
			caps = "MMC_CAP_8_BIT_DATA", "MMC_CAP_MMC_HIGHSPEED",
				 "MMC_CAP_SD_HIGHSPEED", "MMC_CAP_NONREMOVABLE", "MMC_CAP_1_8V_DDR",
				 "MMC_CAP_HW_RESET", "MMC_CAP_ERASE", "MMC_CAP_CMD23";
			caps2 = "MMC_CAP2_HS200", "MMC_CAP2_HS400";
			f_min = < 0x493e0 >; //300000
			f_max = < 0x5f5e100 >; //100000000
			max_req_size = < 0x20000 >;	/**256KB*/
			gpio_dat3 = < &gpio		BOOT_3	 GPIO_ACTIVE_HIGH >;	/* BOOT_3: 0x1d */
			hw_reset = < &gpio		BOOT_9	 GPIO_ACTIVE_HIGH >;	/* BOOT_9: 0x23 */
			card_type = < 0x01 >;	/* 1: mmc card(include eMMC), 2: sd card(include tSD), */
		};
	};

	sd {
		compatible = "amlogic, aml_sd_emmc";
		dev_name = "aml_newsd.0";
		status = "okay";
		reg = < 0x00 0xd0072000 0x00 0x2000 >;
		interrupts = < 0x00 0xd9 0x01
				0x00 0x43 0x01
				0x00 0x45 0x01 >;
		pinctrl-names = "sd_clk_cmd_pins", "sd_all_pins", "sd_1bit_pins", "sd_clk_cmd_uart_pins", "sd_1bit_uart_pins", "sd_to_ao_uart_pins", "ao_to_sd_uart_pins", "ao_to_sd_jtag_pins", "sd_to_ao_jtag_pins";
		pinctrl-0 = < &sd_clk_cmd_pins >;
		pinctrl-1 = < &sd_all_pins >;
		pinctrl-2 = < &sd_1bit_pins >;
		pinctrl-3 = < &sd_clk_cmd_uart_pins >;
		pinctrl-4 = < &sd_1bit_uart_pins >;
		pinctrl-5 = < &sd_to_ao_uart_pins >;
		pinctrl-6 = < &ao_to_sd_uart_pins >;
		pinctrl-7 = < &ao_to_sd_jtag_pins >;
		pinctrl-8 = < &sd_to_ao_jtag_pins >;

		sd {
			status = "okay";
			pinname = "sd";
			ocr_avail = < 0x200080 >; //3.3: 0x200000, 1.8+3.3: 0x00200080
			caps = "MMC_CAP_4_BIT_DATA", "MMC_CAP_MMC_HIGHSPEED", "MMC_CAP_SD_HIGHSPEED";
					//"MMC_CAP_UHS_SDR12",
					//"MMC_CAP_UHS_SDR25", "MMC_CAP_UHS_SDR50",
					//"MMC_CAP_UHS_SDR104";
			f_min = < 0x61a80 >; //400000
			f_max = < 0x5f5e100 >; //100000000
			max_req_size = < 0x20000 >;	/**128KB*/
			gpio_dat3 = < &gpio		CARD_4		GPIO_ACTIVE_HIGH >;	/* CARD_4: 0x2e */
			jtag_pin = < &gpio		CARD_0		GPIO_ACTIVE_HIGH >;	/* CARD_0: 0x2a */
			gpio_cd = < &gpio		CARD_6		GPIO_ACTIVE_HIGH >;	/* CARD_6: 0x30 */
			irq_in = < 0x03 >;
			irq_out = < 0x05 >;
			card_type = < 0x05 >;	/* 0: unknown, 1: mmc card(include eMMC), 2: sd card(include tSD), 3: sdio device(ie: sdio-wifi), 4: SD combo (IO+mem) card, 5: NON sdio device(means sd/mmc card), other: reserved */
		};
	};

	sdio {
		compatible = "amlogic, aml_sd_emmc";
		dev_name = "aml_newsd.0";
		status = "okay";
		reg = < 0x00 0xd0070000 0x00 0x2000 >;
		interrupts = < 0x00 0xd8 0x04 >;
		pinctrl-names = "sdio_clk_cmd_pins", "sdio_all_pins";
		pinctrl-0 = < &sdio_clk_cmd_pins >;
		pinctrl-1 = < &sdio_all_pins >;

		sdio {
			status = "okay";
			pinname = "sdio";
			ocr_avail = < 0x00200080 >;	/*3.3: 0x200000, 1.8+3.3: 0x00200080 */
			caps = "MMC_CAP_4_BIT_DATA", "MMC_CAP_MMC_HIGHSPEED",
				"MMC_CAP_SD_HIGHSPEED", "MMC_CAP_NONREMOVABLE",
				"MMC_CAP_UHS_SDR12", "MMC_CAP_UHS_SDR25",
				"MMC_CAP_UHS_SDR50", "MMC_CAP_UHS_SDR104",
				"MMC_PM_KEEP_POWER", "MMC_CAP_SDIO_IRQ";
			f_min = < 0x61a80 >; //400000
			f_max = < 0xbebc200 >; //200000000
			// vol_switch_delay = < 10 >;
			max_req_size = < 0x20000 >;		 /**128KB*/
			card_type = < 0x03 >;	/*3: sdio device(ie: sdio-wifi), 4: SD combo (IO+mem) card, */
		};
	};

	nand {
		compatible = "amlogic, aml_nand";
		dev_name = "nand";
		status = "disabled";
		reg = < 0x00 0xd0074800 0x00 0x200 >;
		interrupts = < 0x00 0x22 0x01 >;
		pinctrl-names = "nand_rb_mod", "nand_norb_mod", "nand_cs_pins_only";
		pinctrl-0 = < &conf_nand_pulldown &conf_nand_pullup &all_nand_pins >;
		pinctrl-1 = < &conf_nand_pulldown &conf_nand_pullup &all_nand_pins >;
		pinctrl-2 = < &nand_cs_pins >;
		device_id = < 0x00 >;
		plat-names = "nandnormal";
		plat-num = < 0x01 >;
		plat-part-0 = < &normal >;
		normal: normal{
			enable_pad = "ce0", "ce1", "ce2", "ce3";
			busy_pad = "rb0";
		};
	};

	aml_nftl {
		compatible = "amlogic, nftl";
		/* config nftl here */
	};

	partitions {
		parts = < 0x0c >;
		part-0 = < &logo >;
		part-1 = < &recovery >;
		part-2 = < &rsv >;
		part-3 = < &tee >;
		part-4 = < &crypt >;
		part-5 = < &misc >;
		part-6 = < &instaboot >;
		part-7 = < &boot >;
		part-8 = < &system >;
		part-9 = < &chaomi >;
		part-10 = < &cache >;
		part-11 = < &data >;

		logo: logo {
			pname = "logo";
			size = < 0x00 0x2000000 >;
			mask = < 0x01 >;
		};

		recovery: recovery {
			pname = "recovery";
			size = < 0x00 0x2000000 >;
			mask = < 0x01 >;
		};

		rsv: rsv {
			pname = "rsv";
			size = < 0x00 0x800000 >;
			mask = < 0x01 >;
		};

		tee: tee {
			pname = "tee";
			size = < 0x00 0x800000 >;
			mask = < 0x01 >;
		};

		crypt: crypt {
			pname = "crypt";
			size = < 0x00 0x2000000 >;
			mask = < 0x01 >;
		};

		misc: misc {
			pname = "misc";
			size = < 0x00 0x2000000 >;
			mask = < 0x01 >;
		};

		instaboot: instaboot {
			pname = "instaboot";
			size = < 0x00 0x20000000 >;
			mask = < 0x01 >;
		};

		boot: boot {
			pname = "boot";
			size = < 0x00 0x2000000 >;
			mask = < 0x01 >;
		};

		system: system {
			pname = "system";
			size = < 0x00 0x40000000 >;
			mask = < 0x01 >;
		};

		chaomi: chaomi {
			pname = "chaomi";
			size = < 0x00 0x60000000 >;
			mask = < 0x01 >;
		};

		cache: cache {
			pname = "cache";
			size = < 0x00 0x20000000 >;
			mask = < 0x02 >;
		};

		data: data {
			pname = "data";
			size = < 0xffffffff 0xffffffff >;
			mask = < 0x04 >;
		};
	};

	unifykey {
		compatible = "amlogic, unifykey";
		status = "ok";

		unifykey-num = < 0x12 >;
		unifykey-index-0 = < &keysn_0 >;
		unifykey-index-1 = < &keysn_1 >;
		unifykey-index-2 = < &keysn_2 >;
		unifykey-index-3 = < &keysn_3 >;
		unifykey-index-4 = < &keysn_4 >;
		unifykey-index-5 = < &keysn_5 >;
		unifykey-index-6 = < &keysn_6 >;
		unifykey-index-7 = < &keysn_7 >;
		unifykey-index-8 = < &keysn_8 >;
		unifykey-index-9 = < &keysn_9 >;
		unifykey-index-10 = < &keysn_10 >;
		unifykey-index-11 = < &keysn_11 >;
		unifykey-index-12 = < &keysn_12 >;
		unifykey-index-13 = < &keysn_13 >;
		unifykey-index-14 = < &keysn_14 >;
		unifykey-index-15 = < &keysn_15 >;
		unifykey-index-16 = < &keysn_16 >;
		unifykey-index-17 = < &keysn_17 >;

		keysn_0: key_0{
			key-name = "usid";
			key-device = "normal";
			key-permit = "read", "write", "del";
		};

		keysn_1: key_1{
			key-name = "mac";
			key-device = "normal";
			key-permit = "read", "write", "del";
		};

		keysn_2: key_2{
			key-name = "hdcp";
			key-device = "secure";
			key-type = "sha1";
			key-permit = "read", "write", "del";
		};

		keysn_3: key_3{
			key-name = "secure_boot_set";
			key-device = "efuse";
			key-permit = "write";
		};

		keysn_4: key_4{
			key-name = "mac_bt";
			key-device = "normal";
			key-permit = "read", "write", "del";
			key-type = "mac";
		};

		keysn_5: key_5{
			key-name = "mac_wifi";
			key-device = "normal";
			key-permit = "read", "write", "del";
			key-type = "mac";
		};

		keysn_6: key_6{
			key-name = "hdcp2_tx";
			key-device = "normal";
			key-permit = "read", "write", "del";
		};

		keysn_7: key_7{
			key-name = "hdcp2_rx";
			key-device = "normal";
			key-permit = "read", "write", "del";
		};

		keysn_8: key_8{
			key-name = "widevinekeybox";
			key-device = "secure";
			key-permit = "read", "write", "del";
		};

		keysn_9: key_9{
			key-name = "deviceid";
			key-device = "normal";
			key-permit = "read", "write", "del";
		};

		keysn_10: key_10{
			key-name = "hdcp22_fw_private";
			key-device = "secure";
			key-permit = "read", "write", "del";
		};

		keysn_11: key_11{
			key-name = "PlayReadykeybox25";
			key-device = "secure";
			key-permit = "read", "write", "del";
		};

		keysn_12: key_12{
			key-name = "prpubkeybox"; //PlayReady
			key-device = "secure";
			key-permit = "read", "write", "del";
		};

		keysn_13: key_13{
			key-name = "prprivkeybox"; //PlayReady
			key-device = "secure";
			key-permit = "read", "write", "del";
		};

		keysn_14: key_14 {
			key-name = "devicetype";
			key-device = "normal";
			key-permit = "read", "write", "del";
		};

		keysn_15: key_15 {
			key-name = "devicelicense";
			key-device = "normal";
			key-permit = "read", "write", "del";
		};

		keysn_16: key_16 {
			key-name = "disk_sn";
			key-device = "normal";
			key-permit = "read", "write", "del";
		};

		keysn_17: key_17 {
			key-name = "qrticket";
			key-device = "normal";
			key-permit = "read", "write", "del";
		};
	};

	amhdmitx: amhdmitx{
		compatible = "amlogic, amhdmitx";
		dev_name = "amhdmitx";
		status = "okay";
		pinctrl-names = "hdmitx_hpd", "hdmitx_ddc";
		pinctrl-0 = < &hdmitx_hpd >;
		pinctrl-1 = < &hdmitx_ddc >;
		/* HPD, 57 + 32 = 89; CEC, 151 + 32 = 183*/
		interrupts = < 0x00 0x39 0x01 >; //57
		interrupt-names = "hdmitx_hpd";
		clocks = < &clock CLK_HDMITX_SYS &clock CLK_HDMITX_ENCP
			&clock CLK_HDMITX_ENCI &clock CLK_HDMITX_PIXEL
			&clock CLK_HDMITX_PHY &clock CLK_VID >;
		clock-names = "hdmitx_clk_sys", "hdmitx_clk_encp", "hdmitx_clk_enci",
			"hdmitx_clk_pixel", "hdmitx_clk_phy", "hdmitx_clk_vid";
		gpio_i2c_en = < 0x01 >;
		#address-cells = < 0x02 >;
		#size-cells = < 0x02 >;
		ranges;
	};

	aocec: aocec{
		compatible = "amlogic, amlogic-aocec";
		device_name = "aocec";
		status = "okay";
		vendor_name = "Amlogic";	/* Max Chars: 8	 */
		vendor_id = < 0x00 >;	/* Refer to http: //standards.ieee.org/develop/regauth/oui/oui.txt	*/
		product_desc = "GXBB Mbox";	/* Max Chars: 16	*/
		cec_osd_string = "MBox";	/* Max Chars: 14	*/
		port_num = < 0x01 >;
		arc_port_mask = < 0x00 >;
		interrupts = < 0x00 0xc7 0x01 >;
		interrupt-names = "hdmi_aocec";
		pinctrl-names = "hdmitx_aocec";
		pinctrl-0 = < &hdmitx_aocec >;
		reg = < 0x00 0xc810023c 0x00 0x04
			0x00 0xc8100000 0x00 0x200 >;
	};

	tvout {
		compatible = "amlogic, tvout";
		dev_name = "tvout";
		status = "okay";
	};

	i2c_gpio: i2c_gpio {
		compatible = "i2c-gpio";
		status = "okay";
		dev_name = "i2c-gpio";
		i2c-gpio,delay-us = < 0x0a >;	/* 50 kHz */
		gpios = < &gpio GPIOH_1 0
			&gpio GPIOH_2 0 >;
		/* GPIOH_1: 0x11, GPIOH_2: 0x12 */
		#address-cells = < 0x02 >;
		#size-cells = < 0x02 >;
		i2c-gpio,timeout-ms = < 0x0a >;

		i2c_gpio_edid: i2c_gpio_edid {
			compatible = "i2c-gpio-edid";
			reg = < 0x50 0x00 0x00 0x00 >;
		};
	};

	uart_AO: serial@c81004c0 {
		compatible = "amlogic, meson-uart";
		reg = < 0x00 0xc81004c0 0x00 0x18 >;
		interrupts = < 0x00 0xc1 0x01 >;
		status = "okay";
		clocks = < &clock CLK_XTAL >;
		clock-names = "clk_uart";
		xtal_tick_en = < 0x01 >;
		fifosize = < 0x40 >;
		pinctrl-names = "default";
		//pinctrl-0 = < &ao_uart_pins >;
		support-sysrq = < 0x00 >;	/* 0 not support , 1 support */
	};

	uart_A: serial@c11084c0 {
		compatible = "amlogic, meson-uart";
		reg = < 0x00 0xc11084c0 0x00 0x18 >;
		interrupts = < 0x00 0x1a 0x01 >;
		status = "okay";
		clocks = < &clock CLK_XTAL >;
		clock-names = "clk_uart";
		fifosize = < 0x80 >;
		pinctrl-names = "default";
		pinctrl-0 = < &a_uart_pins >;
		resets = < &clock GCLK_IDX_UART0 >; /* GCLK_IDX_UART0: 0x0d */
	};

	uart_B: serial@c11084dc {
		compatible = "amlogic, meson-uart";
		reg = < 0x00 0xc11084dc 0x00 0x18 >;
		interrupts = < 0x00 0x4b 0x01 >;
		status = "disable";
		clocks = < &clock CLK_XTAL >;
		clock-names = "clk_uart";
		fifosize = < 0x40 >;
		pinctrl-names = "default";
		pinctrl-0 = < &b_uart_pins >;
		resets = < &clock GCLK_IDX_UART1 >; /* GCLK_IDX_UART1: 0x30 */
	};

	uart_C: serial@c1108700 {
		compatible = "amlogic, meson-uart";
		reg = < 0x00 0xc1108700 0x00 0x18 >;
		interrupts = < 0x00 0x5d 0x01 >;
		status = "disable";
		clocks = < &clock CLK_XTAL >;
		clock-names = "clk_uart";
		fifosize = < 0x40 >;
		pinctrl-names = "default";
		pinctrl-0 = < &c_uart_pins >;
		resets = < &clock GCLK_IDX_UART2 >; /* GCLK_IDX_UART2: 0x4f */
	};

	uart_AO_B: serial@c81004e0 {
		compatible = "amlogic, meson-uart";
		reg = < 0x00 0xc81004e0 0x00 0x18 >;
		interrupts = < 0x00 0xc5 0x01 >;
		status = "disable";
		clocks = < &clock CLK_XTAL >;
		clock-names = "clk_uart";
		fifosize = < 0x40 >;
		pinctrl-names = "default";
		pinctrl-0 = < &ao_b_uart_pins >;
	};

	canvas {
		compatible = "amlogic, meson, canvas";
		dev_name = "amlogic-canvas";
		status = "ok";
		reg = < 0x00 0xc8838000 0x00 0x400 >;
	};

	rdma {
		compatible = "amlogic, meson, rdma";
		dev_name = "amlogic-rdma";
		status = "ok";
		interrupts = < 0x00 0x59 0x01 >;
		interrupt-names = "rdma";
	};

	dwc3: dwc3@c9000000 {
		compatible = "synopsys, dwc3";
		reg = < 0x00 0xc9000000 0x00 0x100000 >;
		interrupts = < 0x00 0x1e 0x04 >;
		usb-phy = < &usb2_phy >, < &usb3_phy >;
		cpu-type = "gxl";
		clock-src = "usb3.0";
	};

	usb2_phy: usb2phy@d0078000 {
		compatible = "amlogic, amlogic-new-usb2";
		portnum = < 0x02 >;
		reg = < 0x00 0xd0078000 0x00 0x80 >;
	};

	usb3_phy: usb3phy@d0078080 {
		compatible = "amlogic, amlogic-new-usb3";
		portnum = < 0x00 >;
		reg = < 0x00 0xd0078080 0x00 0x20 >;
		interrupts = < 0x00 0x10 0x04 >;
		otg = < 0x01 >;
		gpio-vbus-power = "GPIOH_5";
		gpios = < &gpio GPIOZ_21 GPIO_ACTIVE_HIGH >; /* GPIOZ_21: 0x15 */
	};

	dwc2_a {
		compatible = "amlogic,dwc2";
		device_name = "dwc2_a";
		reg = < 0x00 0xc9100000 0x00 0x40000 >;
		status = "okay";
		interrupts = < 0x00 0x1f 0x04 >;
		pl-periph-id = < 0x00 >;	/** lm name */
		clock-src = "usb0";	/** clock src */
		port-id = < 0x00 >;	/** ref to mach/usb.h */
		port-type = < 0x02 >;	/** 0: otg, 1: host, 2: slave */
		port-speed = < 0x00 >;	/** 0: default, high, 1: full */
		port-config = < 0x00 >;	/** 0: default */
		port-dma = < 0x00 >;	/** 0: default, 1: single, 2: incr, 3: incr4, 4: incr8, 5: incr16, 6: disable*/
		port-id-mode = < 0x00 >;	/** 0: hardware, 1: sw_host, 2: sw_slave*/
		usb-fifo = < 0x2d8 >;
		cpu-type = "gxl";
		controller-type = < 0x03 >;	/** 0: normal, 1: otg+dwc3 host only, 2: otg+dwc3 device only*/
		phy-reg = < 0xd0078000 >;
		phy-reg-size = < 0xa0 >;
		resets = < &clock GCLK_IDX_USB_GENERAL
				&clock GCLK_IDX_MISC_USB1_TO_DDR
				&clock GCLK_IDX_USB1 >;
		/* GCLK_IDX_USB_GENERAL: 0x3a, GCLK_IDX_MISC_USB1_TO_DDR: 0x48, GCLK_IDX_USB1: 0x36 */
		reset-names = "usb_general", "usb1", "usb1_to_ddr";
	};

	/* AUDIO MESON8 DEVICES */
	i2s_dai: I2S {
		#sound-dai-cells = < 0x00 >;
		resets = < 
			&clock GCLK_IDX_AIU_AI_TOP_GLUE
			&clock GCLK_IDX_AUD_BUF_ABD
			&clock GCLK_IDX_AIU_I2S_OUT
			&clock GCLK_IDX_AIU_AMCLK_MEASURE
			&clock GCLK_IDX_AIU_AIFIFO2
			&clock GCLK_IDX_AIU_AUD_MIXER
			&clock GCLK_IDX_AIU_MIXER_REG
			&clock GCLK_IDX_AIU_ADC
			&clock GCLK_IDX_AIU_TOP_LEVEL
			&clock GCLK_IDX_AIU_AOCLK
			&clock GCLK_IDX_AUD_IN
		 >;
		reset-names = "top_glue", 
			"aud_buf",
			"i2s_out",
			"amclk_measure",
			"aififo2",
			"aud_mixer",
			"mixer_reg",
			"adc",
			"top_level",
			"aoclk",
			"aud_in";
		clocks = < &clock CLK_MPLL2 >,
			< &clock CLK_AMCLK >;
		clock-names = "mpll2", "mclk";
		compatible = "amlogic, aml-i2s-dai";
	};

	spdif_dai: SPDIF {
		#sound-dai-cells = < 0 >;
		compatible = "amlogic, aml-spdif-dai";
		resets = < &clock GCLK_IDX_AIU_IEC958
			&clock GCLK_IDX_AIU_ICE958_AMCLK >;
		/* GCLK_IDX_AIU_IEC958: 0x27, GCLK_IDX_AIU_ICE958_AMCLK: 0x90 */
		reset-names = "iec958", "iec958_amclk";
		clocks = < &clock CLK_MPLL1 >,
			< &clock CLK_I958 >,
			< &clock CLK_AMCLK >,
			< &clock CLK_SPDIF >,
			< &clock CLK_81 >;
		clock-names = "mpll1", "i958", "mclk", "spdif", "clk_81";
	};

	pcm_dai: PCM {
		#sound-dai-cells = < 0x00 >;
		compatible = "amlogic, aml-pcm-dai";
		pinctrl-names = "aml_audio_btpcm";
		pinctrl-0 = < &audio_btpcm_pins >;
		clocks = < &clock CLK_MPLL0 >,
			< &clock CLK_PCM_MCLK >,
			< &clock CLK_PCM_SCLK >;
		clock-names = "mpll0", "pcm_mclk", "pcm_sclk";
		pcm_mode = < 0x01 >;	/* 0 = slave mode, 1 = master mode */
	};

	i2s_plat: i2s_platform {
		compatible = "amlogic, aml-i2s";
		interrupts = < 0x00 0x1d 0x01 >;
	};

	pcm_plat: pcm_platform {
		compatible = "amlogic, aml-pcm";
	};

	spdif_codec: spdif_codec{
		#sound-dai-cells = < 0x00 >;
		compatible = "amlogic, aml-spdif-codec";
		pinctrl-names = "aml_audio_spdif";
		pinctrl-0 = < &audio_spdif_pins >;
	};

	pcm_codec: pcm_codec{
		#sound-dai-cells = < 0x00 >;
		compatible = "amlogic, pcm2BT-codec";
	};
	/* endof AUDIO MESON8 DEVICES */

	/* AUDIO board specific */
	dummy_codec: dummy{
		#sound-dai-cells = < 0x00 >;
		compatible = "amlogic, aml_dummy_codec";
		status = "disable";
	};

	amlogic_codec: t9015{
		#sound-dai-cells = < 0x00 >;
		compatible = "amlogic, aml_codec_T9015";
		reg = < 0x00 0xc8832000 0x00 0x14 >;
		status = "okay";
	};

	aml_m8_snd {
		compatible = "aml, aml_snd_m8";
		status = "okay";
		aml-sound-card,format = "i2s";
		aml_sound_card,name = "AML-M8AUDIO";
		aml,audio-routing = "Ext Spk", "LOUTL", "Ext Spk", "LOUTR";

		mute_gpio-gpios = < &gpio GPIOH_5 0 >; /* GPIOH_5: 0x15 */
		mute_inv;
		sleep_time = < 0x64 >;
		hp_disable;
		hp_paraments = < 0x320 0x12c 0x00 0x05 0x01 >;
		pinctrl-names = "aml_snd_m8";
		pinctrl-0 = < &audio_pins >;
		cpu_list = < &cpudai0 &cpudai1 &cpudai2 >;
		codec_list = < &codec0 &codec1 &codec2 >;
		plat_list = < &i2s_plat &i2s_plat &pcm_plat >;

		cpudai0: cpudai0 {
			sound-dai = < &i2s_dai >;
		};

		cpudai1: cpudai1 {
			sound-dai = < &spdif_dai >;
		};

		cpudai2: cpudai2 {
			sound-dai = < &pcm_dai >;
		};

		codec0: codec0 {
			sound-dai = < &amlogic_codec >;
		};

		codec1: codec1 {
			sound-dai = < &spdif_codec >;
		};

		codec2: codec2 {
			sound-dai = < &pcm_codec >;
		};
	};
	/* END OF AUDIO board specific */

	gpio_keypad {
		compatible = "amlogic, gpio_keypad";
		status = "okay";
		scan_period = < 0x14 >;
		key_num = < 0x03 >;
		key_name = "resetkey", "wifiap", "power";
		key_code = < 0x57 0x58 0x44 >;
		key_pin = < &gpio_ao GPIOAO_2 GPIO_ACTIVE_HIGH >;	/*GPIOAO_2: 0x02*/
		irq_keyup = < 0x06 >;
		irq_keydown = < 0x07 >;
	};

	aml_sensor0: aml-sensor@0 {
		compatible = "amlogic, aml-thermal";
		device_name = "thermal";
		#thermal-sensor-cells = < 0x01 >;
		cooling_devices {

			cpufreq_cool_cluster0 {
				min_state = < 0xf4240 >; //1000000
				dyn_coeff = < 0x8c >; //140
				cluster_id = < 0x00 >;
				node_name = "cpus";
				device_type = "cpufreq";
			};

			cpucore_cool_cluster0 {
				min_state = < 0x01 >;
				dyn_coeff = < 0x00 >;
				cluster_id = < 0x00 >;
				node_name = "cpu_core_cluster0";
				device_type = "cpucore";
			};

			gpufreq_cool {
				min_state = < 0x190 >; //400
				dyn_coeff = < 0x1b5 >; //437
				cluster_id = < 0x00 >;
				node_name = "mali";
				device_type = "gpufreq";
			};

			gpucore_cool {
				min_state = < 0x01 >;
				dyn_coeff = < 0x00 >;
				cluster_id = < 0x00 >;
				node_name = "thermal_gpu_cores";
				device_type = "gpucore";
			};
		};

		cpu_cluster0: cpu_core_cluster0 {
			#cooling-cells = < 0x02 >;	/* min followed by max */
		};

		gpucore: thermal_gpu_cores {
			#cooling-cells = < 0x02 >;	/* min followed by max */
		};
	};

	thermal-zones {

		soc_thermal {
			polling-delay = < 0x3e8 >; //1000
			polling-delay-passive = < 0x64 >; //100
			sustainable-power = < 0x866 >; //2150
			thermal-sensors = < &aml_sensor0 3 >;

			trips {

				switch_on: trip-point@0 {
					temperature = < 0x11170 >; //70000
					hysteresis = < 0x3e8 >; //1000
					type = "passive";
				};

				control: trip-point@1 {
					temperature = < 0x13880 >; //80000
					hysteresis = < 0x3e8 >; //1000
					type = "passive";
				};

				hot: trip-point@2 {
					temperature = < 0x14c08 >; //85000
					hysteresis = < 0x1388 >; //5000
					type = "hot";
				};

				critical: trip-point@3 {
					temperature = < 0x3f7a0 >; //260000
					hysteresis = < 0x3e8 >; //1000
					type = "critical";
				};
			};

			cooling-maps {

				cpufreq_cooling_map {
					trip = < &control >;
					cooling-device = < &cpus 0 4 >;
					contribution = < 0x400 >; //1024
				};

				cpucore_cooling_map {
					trip = < &control >;
					cooling-device = < &cpu_cluster0 0 3 >;
					contribution = < 0x400 >; //1024
				};

				gpufreq_cooling_map {
					trip = < &control >;
					cooling-device = < &gpu 0 4 >;
					contribution = < 0x400 >; //1024
				};

				gpucore_cooling_map {
					trip = < &control >;
					cooling-device = < &gpucore 0 2 >;
					contribution = < 0x400 >; //1024
				};
			};
		};
	};

	ledlight {
		compatible = "amlogic, ledlight";
		dev_name = "ledlight";
		status = "okay";
		power_gpio_0 = < &power_gpio_b >;
		power_gpio_1 = < &power_gpio_r >;
		power_gpio_2 = < &power_gpio_g >;
		power_gpio_3 = < &power_gpio_breath >;

		power_gpio_b: power_gpio_b {
			led_name = "blue_led";
			led_gpio = < &gpio GPIOW_10 GPIO_ACTIVE_HIGH >; /* GPIOW_10: 0x49 */
			led_active = < GPIO_ACTIVE_LOW >;
			led_type = [ 42 00 ];
		};

		power_gpio_r: power_gpio_r {
			led_name = "red_led";
			led_gpio = < &gpio GPIOW_12 GPIO_ACTIVE_HIGH >; /* GPIOW_12: 0x4b */
			led_active = < GPIO_ACTIVE_LOW >;
			led_type = [ 52 00 ];
		};

		power_gpio_g: power_gpio_g {
			led_name = "green_led";
			led_gpio = < &gpio GPIOW_13 GPIO_ACTIVE_HIGH >; /* GPIOW_13: 0x4c */
			led_active = < GPIO_ACTIVE_LOW >;
			led_type = [ 47 00 ];
		};

		power_gpio_breath: power_gpio_breath {
			led_name = "breath";
			led_gpio = < &gpio_ao GPIOAO_3 GPIO_ACTIVE_HIGH >; /* GPIOAO_3: 0x03 */
			led_active = < GPIO_ACTIVE_LOW >;
			led_type = [ 54 00 ];
		};
	};
};
